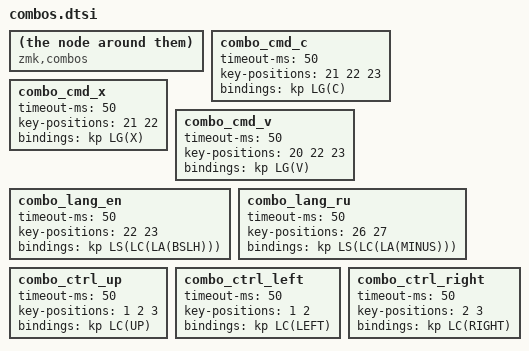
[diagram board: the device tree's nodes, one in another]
/*                KEY POSITIONS

╭────────────────────╮ ╭────────────────────╮
│  0   1   2   3   4 │ │  5   6   7   8   9 │
│ 10  11  12  13  14 │ │ 15  16  17  18  19 │
│ 20  21  22  23  24 │ │ 25  26  27  28  29 │
╰───────────╮ 30  31 │ │ 32  33 ╭───────────╯
            ╰────────╯ ╰────────╯            */

          
compatible = "zmk,combos";
// combo_esc { timeout-ms = <50>; key-positions = <0 1>; bindings = <&kp DOT>; };
// Copy paste
combo_cmd_c { timeout-ms = <50>; key-positions = <21 22 23>; bindings = <&kp LG(C)>; };
combo_cmd_x { timeout-ms = <50>; key-positions = <21 22>; bindings = <&kp LG(X)>; };
combo_cmd_v { timeout-ms = <50>; key-positions = <20 22 23>; bindings = <&kp LG(V)>; };
// Change language
combo_lang_en { timeout-ms = <50>; key-positions = <22 23>; bindings = <&kp LS(LC(LA(BSLH)))>; };
combo_lang_ru { timeout-ms = <50>; key-positions = <26 27>; bindings = <&kp LS(LC(LA(MINUS)))>; };
// Mac Os navigation
combo_ctrl_up { timeout-ms = <50>; key-positions = <1 2 3>; bindings = <&kp LC(UP)>; };
combo_ctrl_left { timeout-ms = <50>; key-positions = <1 2>; bindings = <&kp LC(LEFT)>; };
combo_ctrl_right { timeout-ms = <50>; key-positions = <2 3>; bindings = <&kp LC(RIGHT)>; };
